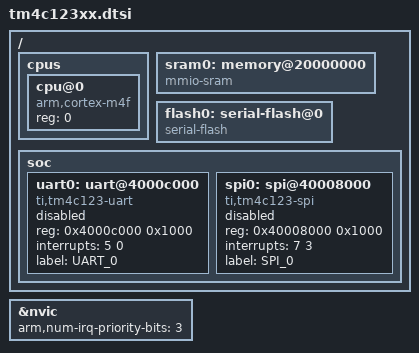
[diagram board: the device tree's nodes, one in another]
#include <arm/armv7-m.dtsi>

/ {
	cpus {
		#address-cells = <1>;
		#size-cells = <0>;
		cpu@0 {
			device_type = "cpu";
			compatible = "arm,cortex-m4f";
			reg = <0>;
		};
	};

	sram0: memory@20000000 {
		compatible = "mmio-sram";
		device_type = "memory";
	};

	flash0: serial-flash@0 {
		compatible = "serial-flash";
	};

	soc {
		uart0: uart@4000c000 {
			compatible = "ti,tm4c123-uart";
			reg = <0x4000c000 0x1000>;
			interrupts = <5 0>; /* 5 = 21(TI uart interrupt num) - 16(zephyr), for compatible zephyr */
			interrupt-names = "status";
			status = "disabled";
			label = "UART_0";
		};

		spi0: spi@40008000 {
			#address-cells = <1>;
			#size-cells = <0>;
			compatible = "ti,tm4c123-spi";
			reg = <0x40008000 0x1000>;
			interrupts = <7 3>; /* 7 = 23(TI uart interrupt num) - 16(zephyr), for compatible zephyr */
			status = "disabled";
			label = "SPI_0";
		};
	};
};

&nvic {
	arm,num-irq-priority-bits = <3>;
};
